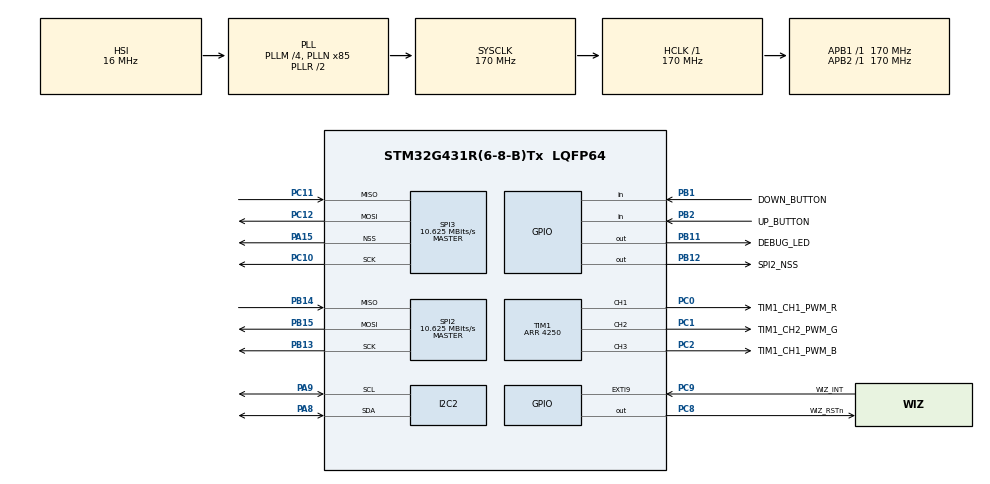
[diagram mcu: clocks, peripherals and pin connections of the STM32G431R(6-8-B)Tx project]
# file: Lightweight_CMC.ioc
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Dma.Request0=SPI2_RX
Dma.Request1=SPI2_TX
Dma.Request2=SPI3_RX
Dma.Request3=SPI3_TX
Dma.SPI2_RX.0.Direction=DMA_PERIPH_TO_MEMORY
Dma.SPI2_RX.0.EventEnable=DISABLE
Dma.SPI2_RX.0.Instance=DMA1_Channel4
Dma.SPI2_RX.0.MemDataAlignment=DMA_MDATAALIGN_BYTE
Dma.SPI2_RX.0.MemInc=DMA_MINC_ENABLE
Dma.SPI2_RX.0.Mode=DMA_NORMAL
Dma.SPI2_RX.0.PeriphDataAlignment=DMA_PDATAALIGN_BYTE
Dma.SPI2_RX.0.PeriphInc=DMA_PINC_DISABLE
Dma.SPI2_RX.0.Polarity=HAL_DMAMUX_REQ_GEN_RISING
Dma.SPI2_RX.0.Priority=DMA_PRIORITY_HIGH
Dma.SPI2_RX.0.RequestNumber=1
Dma.SPI2_RX.0.SignalID=NONE
Dma.SPI2_RX.0.SyncEnable=DISABLE
Dma.SPI2_RX.0.SyncPolarity=HAL_DMAMUX_SYNC_NO_EVENT
Dma.SPI2_RX.0.SyncRequestNumber=1
Dma.SPI2_RX.0.SyncSignalID=NONE
Dma.SPI2_TX.1.Direction=DMA_MEMORY_TO_PERIPH
Dma.SPI2_TX.1.EventEnable=DISABLE
Dma.SPI2_TX.1.Instance=DMA1_Channel5
Dma.SPI2_TX.1.MemDataAlignment=DMA_MDATAALIGN_BYTE
Dma.SPI2_TX.1.MemInc=DMA_MINC_ENABLE
Dma.SPI2_TX.1.Mode=DMA_NORMAL
Dma.SPI2_TX.1.PeriphDataAlignment=DMA_PDATAALIGN_BYTE
Dma.SPI2_TX.1.PeriphInc=DMA_PINC_DISABLE
Dma.SPI2_TX.1.Polarity=HAL_DMAMUX_REQ_GEN_RISING
Dma.SPI2_TX.1.Priority=DMA_PRIORITY_HIGH
Dma.SPI2_TX.1.RequestNumber=1
Dma.SPI2_TX.1.SignalID=NONE
Dma.SPI2_TX.1.SyncEnable=DISABLE
Dma.SPI2_TX.1.SyncPolarity=HAL_DMAMUX_SYNC_NO_EVENT
Dma.SPI2_TX.1.SyncRequestNumber=1
Dma.SPI2_TX.1.SyncSignalID=NONE
Dma.SPI3_RX.2.Direction=DMA_PERIPH_TO_MEMORY
Dma.SPI3_RX.2.EventEnable=DISABLE
Dma.SPI3_RX.2.Instance=DMA1_Channel1
Dma.SPI3_RX.2.MemDataAlignment=DMA_MDATAALIGN_BYTE
Dma.SPI3_RX.2.MemInc=DMA_MINC_ENABLE
Dma.SPI3_RX.2.Mode=DMA_NORMAL
Dma.SPI3_RX.2.PeriphDataAlignment=DMA_PDATAALIGN_BYTE
Dma.SPI3_RX.2.PeriphInc=DMA_PINC_DISABLE
Dma.SPI3_RX.2.Polarity=HAL_DMAMUX_REQ_GEN_RISING
Dma.SPI3_RX.2.Priority=DMA_PRIORITY_LOW
Dma.SPI3_RX.2.RequestNumber=1
Dma.SPI3_RX.2.SignalID=NONE
Dma.SPI3_RX.2.SyncEnable=DISABLE
Dma.SPI3_RX.2.SyncPolarity=HAL_DMAMUX_SYNC_NO_EVENT
Dma.SPI3_RX.2.SyncRequestNumber=1
Dma.SPI3_RX.2.SyncSignalID=NONE
Dma.SPI3_TX.3.Direction=DMA_MEMORY_TO_PERIPH
Dma.SPI3_TX.3.EventEnable=DISABLE
Dma.SPI3_TX.3.Instance=DMA1_Channel2
Dma.SPI3_TX.3.MemDataAlignment=DMA_MDATAALIGN_BYTE
Dma.SPI3_TX.3.MemInc=DMA_MINC_ENABLE
Dma.SPI3_TX.3.Mode=DMA_NORMAL
Dma.SPI3_TX.3.PeriphDataAlignment=DMA_PDATAALIGN_BYTE
Dma.SPI3_TX.3.PeriphInc=DMA_PINC_DISABLE
Dma.SPI3_TX.3.Polarity=HAL_DMAMUX_REQ_GEN_RISING
Dma.SPI3_TX.3.Priority=DMA_PRIORITY_LOW
Dma.SPI3_TX.3.RequestNumber=1
Dma.SPI3_TX.3.SignalID=NONE
Dma.SPI3_TX.3.SyncEnable=DISABLE
Dma.SPI3_TX.3.SyncPolarity=HAL_DMAMUX_SYNC_NO_EVENT
Dma.SPI3_TX.3.SyncRequestNumber=1
Dma.SPI3_TX.3.SyncSignalID=NONE
I2C2.Timing=0x40B285C2
Mcu.Family=STM32G4
Mcu.Name=STM32G431R(6-8-B)Tx
Mcu.Package=LQFP64
NUCLEO-G431RB.BUTTON=1
NUCLEO-G431RB.LD1=true
NUCLEO-G431RB.VCP=false
NVIC.DMA1_Channel1_IRQn=true\:0\:0\:false\:false\:true\:false\:true\:true
NVIC.DMA1_Channel2_IRQn=true\:0\:0\:false\:false\:true\:false\:true\:true
NVIC.DMA1_Channel4_IRQn=true\:0\:0\:false\:false\:true\:false\:true\:true
NVIC.DMA1_Channel5_IRQn=true\:0\:0\:false\:false\:true\:false\:true\:true
NVIC.EXTI15_10_IRQn=true\:0\:0\:false\:false\:true\:false\:true\:true
NVIC.I2C2_ER_IRQn=true\:0\:0\:false\:false\:true\:true\:true\:true
NVIC.I2C2_EV_IRQn=true\:0\:0\:false\:false\:true\:true\:true\:true
NVIC.PriorityGroup=NVIC_PRIORITYGROUP_4
NVIC.SPI3_IRQn=true\:0\:0\:false\:false\:true\:true\:true\:true
PA13.GPIO_Label=T_SWDIO
PA13.Signal=SYS_JTMS-SWDIO
PA14.GPIO_Label=T_SWCLK
PA14.Signal=SYS_JTCK-SWCLK
PA15.Mode=NSS_Signal_Hard_Output
PA15.Signal=SPI3_NSS
PA8.Mode=I2C
PA8.Signal=I2C2_SDA
PA9.Mode=I2C
PA9.Signal=I2C2_SCL
PB1.GPIO_Label=DOWN_BUTTON
PB1.GPIO_PuPd=GPIO_PULLDOWN
PB1.Signal=GPIO_Input
PB11.GPIO_Label=DEBUG_LED
PB11.Signal=GPIO_Output
PB12.GPIO_Label=SPI2_NSS
PB12.Signal=GPIO_Output
PB13.Mode=Full_Duplex_Master
PB13.Signal=SPI2_SCK
PB14.Mode=Full_Duplex_Master
PB14.Signal=SPI2_MISO
PB15.Mode=Full_Duplex_Master
PB15.Signal=SPI2_MOSI
PB2.GPIO_Label=UP_BUTTON
PB2.GPIO_PuPd=GPIO_PULLDOWN
PB2.Signal=GPIO_Input
PB3.GPIO_Label=T_SWO
PB3.Signal=SYS_JTDO-SWO
PC0.GPIO_Label=TIM1_CH1_PWM_R
PC0.Signal=S_TIM1_CH1
PC1.GPIO_Label=TIM1_CH2_PWM_G
PC1.Signal=S_TIM1_CH2
PC10.Mode=Full_Duplex_Master
PC10.Signal=SPI3_SCK
PC11.Mode=Full_Duplex_Master
PC11.Signal=SPI3_MISO
PC12.Mode=Full_Duplex_Master
PC12.Signal=SPI3_MOSI
PC14-OSC32_IN.GPIO_Label=RCC_OSC32_OUT
PC14-OSC32_IN.Signal=RCC_OSC32_IN
PC15-OSC32_OUT.GPIO_Label=RCC_OSC32_OUT
PC15-OSC32_OUT.Signal=RCC_OSC32_OUT
PC2.GPIO_Label=TIM1_CH1_PWM_B
PC2.Signal=S_TIM1_CH3
PC8.GPIO_Label=WIZ_RSTn
PC8.Signal=GPIO_Output
PC9.GPIO_Label=WIZ_INT
PC9.Signal=GPXTI9
PF0-OSC_IN.GPIO_Label=RCC_OSC_IN
PF0-OSC_IN.Signal=RCC_OSC_IN
PF1-OSC_OUT.GPIO_Label=RCC_OSC_OUT
PF1-OSC_OUT.Signal=RCC_OSC_OUT
ProjectManager.HeapSize=0x200
ProjectManager.StackSize=0x400
ProjectManager.TargetToolchain=STM32CubeIDE
RCC.ADC12Freq_Value=170000000
RCC.AHBFreq_Value=170000000
RCC.APB1Freq_Value=170000000
RCC.APB1TimFreq_Value=170000000
RCC.APB2Freq_Value=170000000
RCC.APB2TimFreq_Value=170000000
RCC.CortexFreq_Value=170000000
RCC.EXTERNAL_CLOCK_VALUE=12288000
RCC.HCLKFreq_Value=170000000
RCC.HSE_VALUE=24000000
RCC.HSI48_VALUE=48000000
RCC.HSI_VALUE=16000000
RCC.LSE_VALUE=32768
RCC.PLLM=RCC_PLLM_DIV4
RCC.PLLN=85
RCC.RTCClockSelection=RCC_RTCCLKSOURCE_LSE
RCC.SYSCLKFreq_VALUE=170000000
RCC.SYSCLKSource=RCC_SYSCLKSOURCE_PLLCLK
RCC.USBFreq_Value=170000000
RCC.VCOOutputFreq_Value=340000000
SH.S_TIM1_CH1.0=TIM1_CH1,PWM Generation1 CH1
SH.S_TIM1_CH2.0=TIM1_CH2,PWM Generation2 CH2
SH.S_TIM1_CH3.0=TIM1_CH3,PWM Generation3 CH3
SPI2.BaudRatePrescaler=SPI_BAUDRATEPRESCALER_16
SPI2.CalculateBaudRate=10.625 MBits/s
SPI2.DataSize=SPI_DATASIZE_8BIT
SPI2.Direction=SPI_DIRECTION_2LINES
SPI2.Mode=SPI_MODE_MASTER
SPI2.VirtualType=VM_MASTER
SPI3.BaudRatePrescaler=SPI_BAUDRATEPRESCALER_16
SPI3.CalculateBaudRate=10.625 MBits/s
SPI3.DataSize=SPI_DATASIZE_8BIT
SPI3.Direction=SPI_DIRECTION_2LINES
SPI3.Mode=SPI_MODE_MASTER
SPI3.NSSPMode=SPI_NSS_PULSE_DISABLE
SPI3.VirtualNSS=VM_NSSHARD
SPI3.VirtualType=VM_MASTER
TIM1.AutoReloadPreload=TIM_AUTORELOAD_PRELOAD_ENABLE
TIM1.Channel-PWM\ Generation1\ CH1=TIM_CHANNEL_1
TIM1.Channel-PWM\ Generation2\ CH2=TIM_CHANNEL_2
TIM1.Channel-PWM\ Generation3\ CH3=TIM_CHANNEL_3
TIM1.PeriodNoDither=4250
VP_NUCLEO-G431RB_VS_BSP_COMMON.Mode=COMMON
VP_SYS_VS_DBSignals.Mode=DisableDeadBatterySignals
board=NUCLEO-G431RB

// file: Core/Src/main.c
/* USER CODE BEGIN Header */
/**
  ******************************************************************************
  * @file           : main.c
  * @brief          : Main program body
  ******************************************************************************
  * @attention
  *
  * Copyright (c) 2026 STMicroelectronics.
  * All rights reserved.
  *
  * This software is licensed under terms that can be found in the LICENSE file
  * in the root directory of this software component.
  * If no LICENSE file comes with this software, it is provided AS-IS.
  *
  ******************************************************************************
  */
/* USER CODE END Header */
#include "main.h"
#include "dma.h"
#include "i2c.h"
#include "spi.h"
#include "tim.h"
#include "gpio.h"

/* USER CODE BEGIN Includes */
#include "app/main_loop/main_loop.h"
#include "app/log/log.h"
/* USER CODE END Includes */

void SystemClock_Config(void);

int main(void)
{

  /* MCU Configuration--------------------------------------------------------*/

  /* Reset of all peripherals, Initializes the Flash interface and the Systick. */
  HAL_Init();

  /* Configure the system clock */
  SystemClock_Config();

  /* Initialize all configured peripherals */
  MX_GPIO_Init();
  MX_DMA_Init();
  MX_SPI2_Init();
  MX_SPI3_Init();
  MX_TIM1_Init();
  MX_I2C2_Init();

  /* Initialize leds */
  BSP_LED_Init(LED_GREEN);

  /* Initialize USER push-button, will be used to trigger an interrupt each time it's pressed.*/
  BSP_PB_Init(BUTTON_USER, BUTTON_MODE_EXTI);

  /* Infinite loop */
  /* USER CODE BEGIN WHILE */
  /* (Nucleo BSP LED/button init removed — this board defines its own
   *  pins in the .ioc: DEBUG_LED on PB11, UP_BUTTON/DOWN_BUTTON on PB1/PB2.
   *  Those pins are configured by MX_GPIO_Init from CubeMX; no BSP needed.) */
  main_loop_init();
  main_loop_run();          /* never returns */

  while (1)
  {

    /* USER CODE END WHILE */

  }
}

void SystemClock_Config(void)
{
  RCC_OscInitTypeDef RCC_OscInitStruct = {0};
  RCC_ClkInitTypeDef RCC_ClkInitStruct = {0};

  /** Configure the main internal regulator output voltage
  */
  HAL_PWREx_ControlVoltageScaling(PWR_REGULATOR_VOLTAGE_SCALE1_BOOST);

  /** Initializes the RCC Oscillators according to the specified parameters
  * in the RCC_OscInitTypeDef structure.
  */
  RCC_OscInitStruct.OscillatorType = RCC_OSCILLATORTYPE_HSI;
  RCC_OscInitStruct.HSIState = RCC_HSI_ON;
  RCC_OscInitStruct.HSICalibrationValue = RCC_HSICALIBRATION_DEFAULT;
  RCC_OscInitStruct.PLL.PLLState = RCC_PLL_ON;
  RCC_OscInitStruct.PLL.PLLSource = RCC_PLLSOURCE_HSI;
  RCC_OscInitStruct.PLL.PLLM = RCC_PLLM_DIV4;
  RCC_OscInitStruct.PLL.PLLN = 85;
  RCC_OscInitStruct.PLL.PLLP = RCC_PLLP_DIV2;
  RCC_OscInitStruct.PLL.PLLQ = RCC_PLLQ_DIV2;
  RCC_OscInitStruct.PLL.PLLR = RCC_PLLR_DIV2;
  if (HAL_RCC_OscConfig(&RCC_OscInitStruct) != HAL_OK)
  {
    Error_Handler();
  }

  /** Initializes the CPU, AHB and APB buses clocks
  */
  RCC_ClkInitStruct.ClockType = RCC_CLOCKTYPE_HCLK|RCC_CLOCKTYPE_SYSCLK
                              |RCC_CLOCKTYPE_PCLK1|RCC_CLOCKTYPE_PCLK2;
  RCC_ClkInitStruct.SYSCLKSource = RCC_SYSCLKSOURCE_PLLCLK;
  RCC_ClkInitStruct.AHBCLKDivider = RCC_SYSCLK_DIV1;
  RCC_ClkInitStruct.APB1CLKDivider = RCC_HCLK_DIV1;
  RCC_ClkInitStruct.APB2CLKDivider = RCC_HCLK_DIV1;

  if (HAL_RCC_ClockConfig(&RCC_ClkInitStruct, FLASH_LATENCY_4) != HAL_OK)
  {
    Error_Handler();
  }
}

void Error_Handler(void)
{
  /* USER CODE BEGIN Error_Handler_Debug */
  /* Log if possible, then spin. The watchdog is not enabled yet (see
   * Documentation/architecture.md §7.1) so there is no automatic reset
   * — manual power-cycle required if you land here. */
  LOG_ERROR("Error_Handler invoked");
  __disable_irq();
  while (1) { }
  /* USER CODE END Error_Handler_Debug */
}
